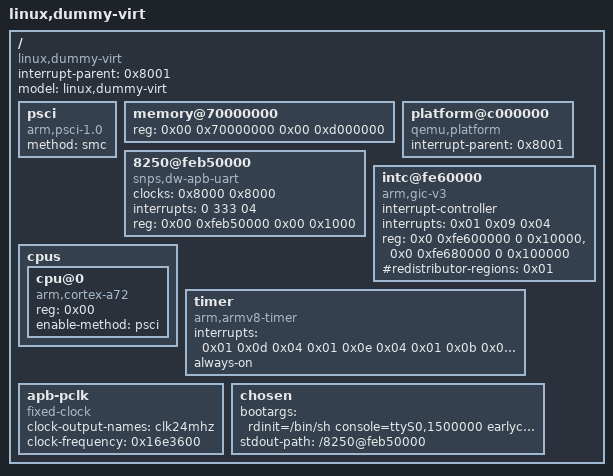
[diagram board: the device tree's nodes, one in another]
/dts-v1/;
/ {
	interrupt-parent = <0x8001>;
	model = "linux,dummy-virt";
	#size-cells = <0x02>;
	#address-cells = <0x02>;
	compatible = "linux,dummy-virt";

	psci {
		method = "smc";
		compatible = "arm,psci-1.0";
	};

	// ok
	memory@70000000 {
		reg = <0x00 0x70000000 0x00 0xd000000>;
		device_type = "memory";
	};

	platform@c000000 {
		interrupt-parent = <0x8001>;
		ranges = <0x00 0x00 0xc000000 0x2000000>;
		#address-cells = <0x01>;
		#size-cells = <0x01>;
		compatible = "qemu,platform\0simple-bus";
	};

	8250@feb50000 {
		clock-names = "apb_pclk";
		clocks = <0x8000 0x8000>;
		interrupts = <0 333 04>;
		reg = <0x00 0xfeb50000 0x00 0x1000>;
		compatible = "snps,dw-apb-uart";
	};

	intc@fe60000 {
		phandle = <0x8001>;
	   	#interrupt-cells = <3>;
    		#address-cells = <2>;
    		#size-cells = <2>;
		ranges;
		interrupt-controller;
		interrupts = <0x01 0x09 0x04>;
		reg = <0x0 0xfe600000 0 0x10000>,
		      <0x0 0xfe680000 0 0x100000>;
		#redistributor-regions = <0x01>;
		compatible = "arm,gic-v3";
	};

	cpus {
		#size-cells = <0x00>;
		#address-cells = <0x01>;
		cpu@0 {
			reg = <0x00>;
			compatible = "arm,cortex-a72";
			device_type = "cpu";
			enable-method = "psci";
		};
	};

	timer {
		interrupts = 
		<0x01 0x0d 0x04 0x01 0x0e 0x04 0x01 0x0b 0x04 0x01 0x0a 0x04>;
		always-on;
		compatible = "arm,armv8-timer";
	};

	apb-pclk {
		phandle = <0x8000>;
		clock-output-names = "clk24mhz";
		clock-frequency = <0x16e3600>;
		#clock-cells = <0x00>;
		compatible = "fixed-clock";
	};

	chosen {
		bootargs = "rdinit=/bin/sh console=ttyS0,1500000 earlycon=uart8250,mmio32,0xfeb50000";
		stdout-path = "/8250@feb50000";
	};
};
